# AT32F407xx register map
Vendor: Keil; Series: AT32F407; File version: 1.0
CPU: CM4 r0p1, little endian, no MPU, FPU, 4 interrupt priority bits
Registers are 32-bit, read-write, reset 0x0 unless marked. A register's access mark holds for its fields unless they carry their own. Offsets are from the block's base; [hi:lo] are bit positions; {n}, {i} and the like mark numbered series; 'fields as' and 'values as' point back to an identical list.

## MCUDBG — Debug support
Base 0xE0042000
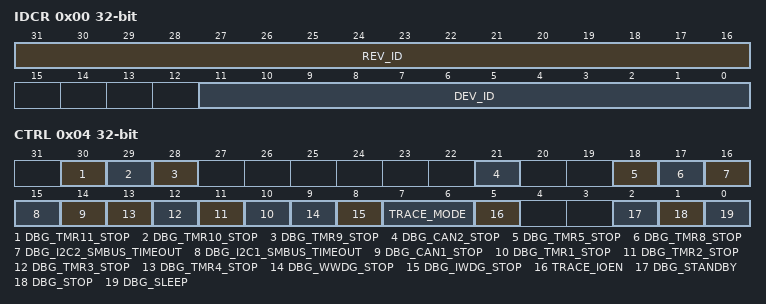
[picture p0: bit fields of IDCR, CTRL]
0x00 IDCR ro — MCUDBG_IDCODE
  [31:16] REV_ID, [11:0] DEV_ID
0x04 CTRL — MCUDBG_CTRL
  [30] DBG_TMR11_STOP
  [29] DBG_TMR10_STOP
  [28] DBG_TMR9_STOP
  [21] DBG_CAN2_STOP
  [18] DBG_TMR5_STOP — DBG_TIM5_STOP
  [17] DBG_TMR8_STOP — DBG_TIM8_STOP
  [16] DBG_I2C2_SMBUS_TIMEOUT
  [15] DBG_I2C1_SMBUS_TIMEOUT
  [14] DBG_CAN1_STOP
  [n+9] DBG_TMR{n}_STOP (n=1..4) — DBG_TIM{n}_STOP
  [9] DBG_WWDG_STOP
  [8] DBG_IWDG_STOP
  [7:6] TRACE_MODE
  [5] TRACE_IOEN
  [2] DBG_STANDBY
  [1] DBG_STOP
  [0] DBG_SLEEP

## UART4 — Universal asynchronous receiver transmitter
Base 0x40004C00
Same registers: UART5 0x40005000, UART7 0x40016400, UART8 0x40016800
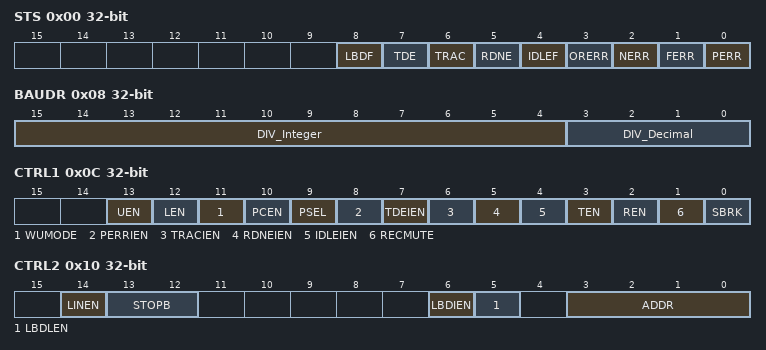
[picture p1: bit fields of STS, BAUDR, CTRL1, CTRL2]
0x00 STS — UART4_STS
  [8] LBDF — LIN break detection flag
  [7] TDE ro — Transmit data register empty
  [6] TRAC — Transmission complete
  [5] RDNE — Read data register not empty
  [4] IDLEF ro — IDLE line detected
  [3] ORERR ro — Overrun error
  [2] NERR ro — Noise error flag
  [1] FERR ro — Framing error
  [0] PERR ro — Parity error
0x04 DT — UART4_DR
  [8:0] DT — DR
0x08 BAUDR — UART4_BAUDR
  [15:4] DIV_Integer — DIV_Mantissa
  [3:0] DIV_Decimal — DIV_Fraction
0x0C CTRL1 — UART4_CTRL1
  [13] UEN — USART enable
  [12] LEN — Word length
  [11] WUMODE — Wakeup method
  [10] PCEN — Parity control enable
  [9] PSEL — Parity selection
  [8] PERRIEN — PE interrupt enable
  [7] TDEIEN — TXE interrupt enable
  [6] TRACIEN — Transmission complete interrupt enable
  [5] RDNEIEN — RXNE interrupt enable
  [4] IDLEIEN — IDLE interrupt enable
  [3] TEN — Transmitter enable
  [2] REN — Receiver enable
  [1] RECMUTE — Receiver wakeup
  [0] SBRK — Send break
0x10 CTRL2 — UART4_CTRL2
  [14] LINEN — LIN mode enable
  [13:12] STOPB — STOP bits
  [6] LBDIEN — LIN break detection interrupt enable
  [5] LBDLEN — lin break detection length
  [3:0] ADDR — Address of the USART node
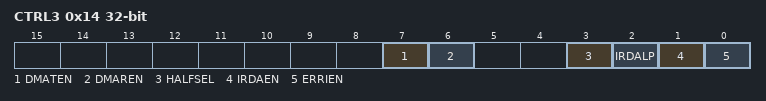
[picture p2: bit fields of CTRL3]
0x14 CTRL3 — UART4_CTRL3
  [7] DMATEN — DMA enable transmitter
  [6] DMAREN — DMA enable receiver
  [3] HALFSEL — Half-duplex selection
  [2] IRDALP — IrDA low-power
  [1] IRDAEN — IrDA mode enable
  [0] ERRIEN — Error interrupt enable

## CRC — CRC calculation unit
Base 0x40023000
0x00 DT reset 0xFFFFFFFF — Data register
  [31:0] DR — Data Register
0x04 IDT — Independent Data register
  [0] IDR
0x08 CTRL — Control register
  [0] RESET — Reset bit

## FMC
Base 0x40022000
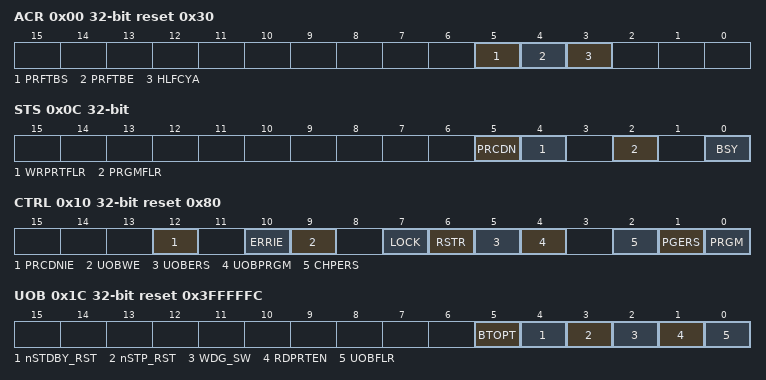
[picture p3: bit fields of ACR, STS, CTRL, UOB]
0x00 ACR reset 0x30 — Flash access control register
  [5] PRFTBS ro — Prefetch buffer status
  [4] PRFTBE — Prefetch buffer enable
  [3] HLFCYA — Flash half cycle access enable
0x04 FCKEY wo — Flash key register
  [31:0] KEY — FPEC key
0x08 OPTKEYR wo — Flash option key register
  [31:0] OPTKEYR — Option byte key
0x0C STS — Status register
  [5] PRCDN — End of operation
  [4] WRPRTFLR — Write protection error
  [2] PRGMFLR — Programming error
  [0] BSY ro — Busy
0x10 CTRL reset 0x80 — Control register
  [12] PRCDNIE — End of operation interrupt enable
  [10] ERRIE — Error interrupt enable
  [9] UOBWE — Option bytes write enable
  [7] LOCK
  [6] RSTR — Start
  [5] UOBERS — Option byte erase
  [4] UOBPRGM — Option byte programming
  [2] CHPERS — Mass Erase
  [1] PGERS — Page Erase
  [0] PRGM — Programming
0x14 ADDR wo — Flash address register
  [31:0] TA — Flash Address
0x1C UOB ro reset 0x3FFFFFC — Option byte register
  [5] BTOPT
  [4] nSTDBY_RST
  [3] nSTP_RST
  [2] WDG_SW
  [1] RDPRTEN — Read protection
  [0] UOBFLR — Option byte error
0x20 WRPRT ro reset 0xFFFFFFFF — Write protection register
  [31:0] WRPRTBMP — Write protect
0x44 FCKEY2 wo — Fpec key
  [31:0] KEY — Write protect
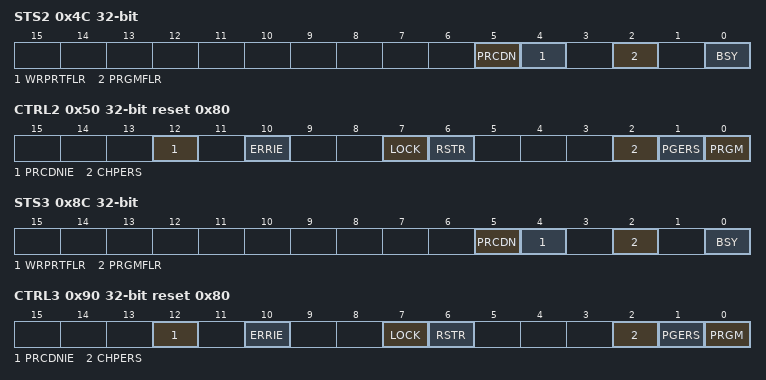
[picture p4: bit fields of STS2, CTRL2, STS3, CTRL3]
0x4C STS2 — Status
  [5] PRCDN
  [4] WRPRTFLR — nSTDBY_RST
  [2] PRGMFLR
  [0] BSY ro — Option byte error
0x50 CTRL2 reset 0x80 — Control register
  [12] PRCDNIE — End of operation interrupt enable
  [10] ERRIE — Error interrupt enable
  [7] LOCK
  [6] RSTR — Start
  [2] CHPERS — Mass Erase
  [1] PGERS — Page Erase
  [0] PRGM — Programming
0x54 ADDR2 wo — Flash address register
  [31:0] TA — Flash Address
0x84 FCKEY3 wo — Fpec key
  [31:0] KEY — Write protect
0x88 SELECT wo
  [31:0] SELECT — Write protect
0x8C STS3 — Status
  fields as STS2
0x90 CTRL3 reset 0x80 — Control register
  fields as CTRL2
0x94 ADDR3 wo — Flash address register
  [31:0] TA — Flash Address
0x98 DA
  [31:0] FDA
0xCC SLIB_STS0
  [3] FSLIB_SLIB_EN read
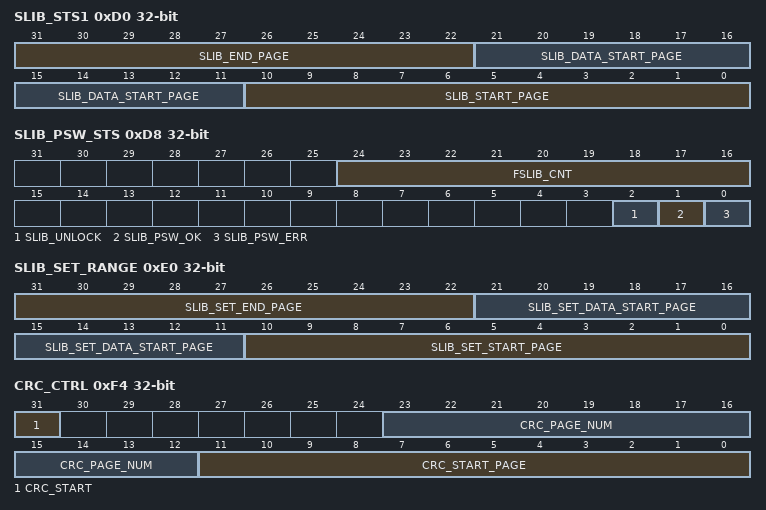
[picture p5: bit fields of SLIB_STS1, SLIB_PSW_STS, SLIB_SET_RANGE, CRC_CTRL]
0xD0 SLIB_STS1
  [31:22] SLIB_END_PAGE read — SLIB End Page Number
  [21:11] SLIB_DATA_START_PAGE read — SLIB Data Start Page Number
  [10:0] SLIB_START_PAGE read — SLIB Start Page Number
0xD4 SLIB_PSW_CLR write — SLIB password register
0xD8 SLIB_PSW_STS — SLIB password state register
  [24:16] FSLIB_CNT read — Counter of remaining SLIB CFG
  [2] SLIB_UNLOCK read
  [1] SLIB_PSW_OK read — SLIB password match
  [0] SLIB_PSW_ERR read — SLIB password mismatch
0xDC SLIB_SET_PSW write — Configure SLIB password
  [31:0] FSLIB_SET_PSW
0xE0 SLIB_SET_RANGE write — Configure SLIB page range
  [31:22] SLIB_SET_END_PAGE — SLIB End Page Number, Valid input: 0~511
  [21:11] SLIB_SET_DATA_START_PAGE — SLIB Data Start Page Number, Valid input: 0~511, 0 means no data area
  [10:0] SLIB_SET_START_PAGE — SLIB Start Page Number, Valid input: 0~511
0xF0 SLIB_KEYR write — SLIB unlock key register
  [31:0] FSLIB_KEYR
0xF4 CRC_CTRL wo — Flash crc ctrl register
  [31] CRC_START, [23:12] CRC_PAGE_NUM, [11:0] CRC_START_PAGE
0xF8 CRC_OUTR ro — Flash crc output register
  [31:0] CRC_OUT

## Notices in the file
Copyright (C) 2012-2014 ARM Limited. All rights reserved.
Purpose: System Viewer Description (SVD) Example (Schema Version 1.1)
This is a description of a none-existent and incomplete device
for demonstration purposes only.
Redistribution and use in source and binary forms, with or without
modification, are permitted provided that the following conditions are met:
- Redistributions of source code must retain the above copyright
notice, this list of conditions and the following disclaimer.
- Redistributions in binary form must reproduce the above copyright
notice, this list of conditions and the following disclaimer in the
documentation and/or other materials provided with the distribution.
- Neither the name of ARM nor the names of its contributors may be used
to endorse or promote products derived from this software without
specific prior written permission.
THIS SOFTWARE IS PROVIDED BY THE COPYRIGHT HOLDERS AND CONTRIBUTORS "AS IS"
AND ANY EXPRESS OR IMPLIED WARRANTIES, INCLUDING, BUT NOT LIMITED TO, THE
IMPLIED WARRANTIES OF MERCHANTABILITY AND FITNESS FOR A PARTICULAR PURPOSE
ARE DISCLAIMED. IN NO EVENT SHALL COPYRIGHT HOLDERS AND CONTRIBUTORS BE
LIABLE FOR ANY DIRECT, INDIRECT, INCIDENTAL, SPECIAL, EXEMPLARY, OR
CONSEQUENTIAL DAMAGES (INCLUDING, BUT NOT LIMITED TO, PROCUREMENT OF
SUBSTITUTE GOODS OR SERVICES; LOSS OF USE, DATA, OR PROFITS; OR BUSINESS
INTERRUPTION) HOWEVER CAUSED AND ON ANY THEORY OF LIABILITY, WHETHER IN
CONTRACT, STRICT LIABILITY, OR TORT (INCLUDING NEGLIGENCE OR OTHERWISE)
ARISING IN ANY WAY OUT OF THE USE OF THIS SOFTWARE, EVEN IF ADVISED OF THE
POSSIBILITY OF SUCH DAMAGE.
